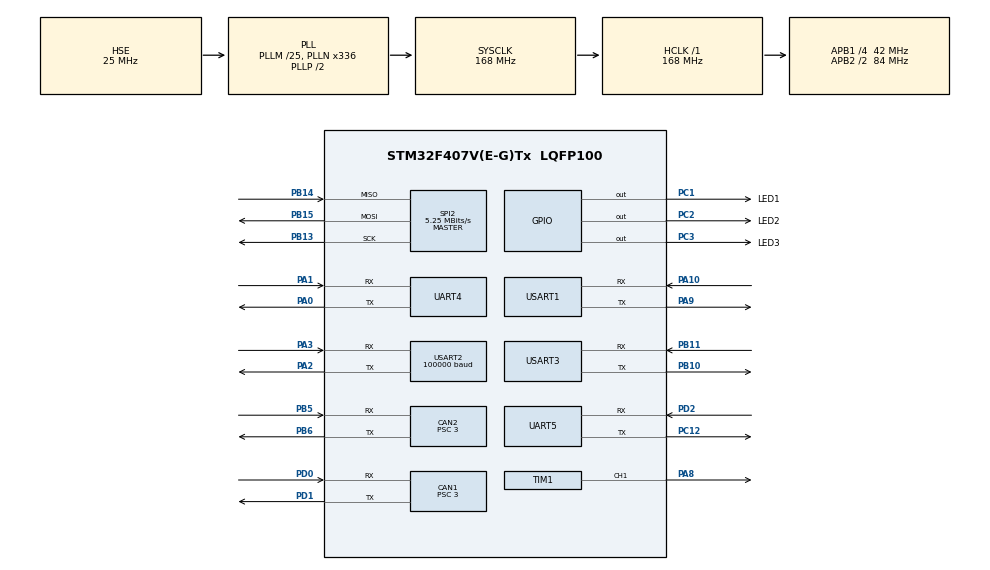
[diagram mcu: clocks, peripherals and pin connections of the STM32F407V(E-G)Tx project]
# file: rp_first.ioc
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CAN1.ABOM=ENABLE
CAN1.BS1=CAN_BS1_9TQ
CAN1.BS2=CAN_BS2_4TQ
CAN1.CalculateBaudRate=1000000
CAN1.CalculateTimeBit=1000
CAN1.CalculateTimeQuantum=71.42857142857143
CAN1.Prescaler=3
CAN2.ABOM=ENABLE
CAN2.BS1=CAN_BS1_9TQ
CAN2.BS2=CAN_BS2_4TQ
CAN2.CalculateBaudRate=1000000
CAN2.CalculateTimeBit=1000
CAN2.CalculateTimeQuantum=71.42857142857143
CAN2.Prescaler=3
Dma.Request0=UART4_RX
Dma.Request1=UART4_TX
Dma.Request2=USART1_RX
Dma.Request3=USART1_TX
Dma.Request4=UART5_RX
Dma.Request5=UART5_TX
Dma.Request6=USART2_RX
Dma.Request7=USART3_RX
Dma.Request8=USART3_TX
Dma.UART4_RX.0.Direction=DMA_PERIPH_TO_MEMORY
Dma.UART4_RX.0.FIFOMode=DMA_FIFOMODE_DISABLE
Dma.UART4_RX.0.Instance=DMA1_Stream2
Dma.UART4_RX.0.MemDataAlignment=DMA_MDATAALIGN_BYTE
Dma.UART4_RX.0.MemInc=DMA_MINC_ENABLE
Dma.UART4_RX.0.Mode=DMA_CIRCULAR
Dma.UART4_RX.0.PeriphDataAlignment=DMA_PDATAALIGN_BYTE
Dma.UART4_RX.0.PeriphInc=DMA_PINC_DISABLE
Dma.UART4_RX.0.Priority=DMA_PRIORITY_HIGH
Dma.UART4_TX.1.Direction=DMA_MEMORY_TO_PERIPH
Dma.UART4_TX.1.FIFOMode=DMA_FIFOMODE_DISABLE
Dma.UART4_TX.1.Instance=DMA1_Stream4
Dma.UART4_TX.1.MemDataAlignment=DMA_MDATAALIGN_BYTE
Dma.UART4_TX.1.MemInc=DMA_MINC_ENABLE
Dma.UART4_TX.1.Mode=DMA_NORMAL
Dma.UART4_TX.1.PeriphDataAlignment=DMA_PDATAALIGN_BYTE
Dma.UART4_TX.1.PeriphInc=DMA_PINC_DISABLE
Dma.UART4_TX.1.Priority=DMA_PRIORITY_HIGH
Dma.UART5_RX.4.Direction=DMA_PERIPH_TO_MEMORY
Dma.UART5_RX.4.FIFOMode=DMA_FIFOMODE_DISABLE
Dma.UART5_RX.4.Instance=DMA1_Stream0
Dma.UART5_RX.4.MemDataAlignment=DMA_MDATAALIGN_BYTE
Dma.UART5_RX.4.MemInc=DMA_MINC_ENABLE
Dma.UART5_RX.4.Mode=DMA_CIRCULAR
Dma.UART5_RX.4.PeriphDataAlignment=DMA_PDATAALIGN_BYTE
Dma.UART5_RX.4.PeriphInc=DMA_PINC_DISABLE
Dma.UART5_RX.4.Priority=DMA_PRIORITY_HIGH
Dma.UART5_TX.5.Direction=DMA_MEMORY_TO_PERIPH
Dma.UART5_TX.5.FIFOMode=DMA_FIFOMODE_DISABLE
Dma.UART5_TX.5.Instance=DMA1_Stream7
Dma.UART5_TX.5.MemDataAlignment=DMA_MDATAALIGN_BYTE
Dma.UART5_TX.5.MemInc=DMA_MINC_ENABLE
Dma.UART5_TX.5.Mode=DMA_NORMAL
Dma.UART5_TX.5.PeriphDataAlignment=DMA_PDATAALIGN_BYTE
Dma.UART5_TX.5.PeriphInc=DMA_PINC_DISABLE
Dma.UART5_TX.5.Priority=DMA_PRIORITY_HIGH
Dma.USART1_RX.2.Direction=DMA_PERIPH_TO_MEMORY
Dma.USART1_RX.2.FIFOMode=DMA_FIFOMODE_DISABLE
Dma.USART1_RX.2.Instance=DMA2_Stream2
Dma.USART1_RX.2.MemDataAlignment=DMA_MDATAALIGN_BYTE
Dma.USART1_RX.2.MemInc=DMA_MINC_ENABLE
Dma.USART1_RX.2.Mode=DMA_CIRCULAR
Dma.USART1_RX.2.PeriphDataAlignment=DMA_PDATAALIGN_BYTE
Dma.USART1_RX.2.PeriphInc=DMA_PINC_DISABLE
Dma.USART1_RX.2.Priority=DMA_PRIORITY_HIGH
Dma.USART1_TX.3.Direction=DMA_MEMORY_TO_PERIPH
Dma.USART1_TX.3.FIFOMode=DMA_FIFOMODE_DISABLE
Dma.USART1_TX.3.Instance=DMA2_Stream7
Dma.USART1_TX.3.MemDataAlignment=DMA_MDATAALIGN_BYTE
Dma.USART1_TX.3.MemInc=DMA_MINC_ENABLE
Dma.USART1_TX.3.Mode=DMA_NORMAL
Dma.USART1_TX.3.PeriphDataAlignment=DMA_PDATAALIGN_BYTE
Dma.USART1_TX.3.PeriphInc=DMA_PINC_DISABLE
Dma.USART1_TX.3.Priority=DMA_PRIORITY_HIGH
Dma.USART2_RX.6.Direction=DMA_PERIPH_TO_MEMORY
Dma.USART2_RX.6.FIFOMode=DMA_FIFOMODE_DISABLE
Dma.USART2_RX.6.Instance=DMA1_Stream5
Dma.USART2_RX.6.MemDataAlignment=DMA_MDATAALIGN_BYTE
Dma.USART2_RX.6.MemInc=DMA_MINC_ENABLE
Dma.USART2_RX.6.Mode=DMA_CIRCULAR
Dma.USART2_RX.6.PeriphDataAlignment=DMA_PDATAALIGN_BYTE
Dma.USART2_RX.6.PeriphInc=DMA_PINC_DISABLE
Dma.USART2_RX.6.Priority=DMA_PRIORITY_HIGH
Dma.USART3_RX.7.Direction=DMA_PERIPH_TO_MEMORY
Dma.USART3_RX.7.FIFOMode=DMA_FIFOMODE_DISABLE
Dma.USART3_RX.7.Instance=DMA1_Stream1
Dma.USART3_RX.7.MemDataAlignment=DMA_MDATAALIGN_BYTE
Dma.USART3_RX.7.MemInc=DMA_MINC_ENABLE
Dma.USART3_RX.7.Mode=DMA_CIRCULAR
Dma.USART3_RX.7.PeriphDataAlignment=DMA_PDATAALIGN_BYTE
Dma.USART3_RX.7.PeriphInc=DMA_PINC_DISABLE
Dma.USART3_RX.7.Priority=DMA_PRIORITY_LOW
Dma.USART3_TX.8.Direction=DMA_MEMORY_TO_PERIPH
Dma.USART3_TX.8.FIFOMode=DMA_FIFOMODE_DISABLE
Dma.USART3_TX.8.Instance=DMA1_Stream3
Dma.USART3_TX.8.MemDataAlignment=DMA_MDATAALIGN_BYTE
Dma.USART3_TX.8.MemInc=DMA_MINC_ENABLE
Dma.USART3_TX.8.Mode=DMA_NORMAL
Dma.USART3_TX.8.PeriphDataAlignment=DMA_PDATAALIGN_BYTE
Dma.USART3_TX.8.PeriphInc=DMA_PINC_DISABLE
Dma.USART3_TX.8.Priority=DMA_PRIORITY_LOW
FREERTOS.Tasks01=MonitorTask,3,256,StartMonitorTask,As weak,NULL,Dynamic,NULL,NULL;CommunityTask,2,512,StartCommunityTask,As weak,NULL,Dynamic,NULL,NULL;ControlTask,0,256,StartControlTask,As weak,NULL,Dynamic,NULL,NULL
FREERTOS.configENABLE_FPU=1
IWDG.Prescaler=IWDG_PRESCALER_8
Mcu.Family=STM32F4
Mcu.Name=STM32F407V(E-G)Tx
Mcu.Package=LQFP100
NVIC.CAN1_RX0_IRQn=true\:5\:0\:false\:false\:true\:true\:true\:true\:true
NVIC.CAN2_RX0_IRQn=true\:5\:0\:false\:false\:true\:true\:true\:true\:true
NVIC.DMA1_Stream0_IRQn=true\:5\:0\:false\:false\:true\:true\:false\:true\:true
NVIC.DMA1_Stream1_IRQn=true\:5\:0\:false\:false\:true\:true\:false\:true\:true
NVIC.DMA1_Stream2_IRQn=true\:5\:0\:false\:false\:true\:true\:false\:true\:true
NVIC.DMA1_Stream3_IRQn=true\:5\:0\:false\:false\:true\:true\:false\:true\:true
NVIC.DMA1_Stream4_IRQn=true\:5\:0\:false\:false\:true\:true\:false\:true\:true
NVIC.DMA1_Stream5_IRQn=true\:5\:0\:false\:false\:true\:true\:false\:true\:true
NVIC.DMA1_Stream7_IRQn=true\:5\:0\:false\:false\:true\:true\:false\:true\:true
NVIC.DMA2_Stream2_IRQn=true\:5\:0\:false\:false\:true\:true\:false\:true\:true
NVIC.DMA2_Stream7_IRQn=true\:5\:0\:false\:false\:true\:true\:false\:true\:true
NVIC.PriorityGroup=NVIC_PRIORITYGROUP_4
NVIC.TIM2_IRQn=true\:15\:0\:false\:false\:true\:false\:false\:true\:true
NVIC.TIM4_IRQn=true\:5\:0\:false\:false\:true\:true\:true\:true\:true
NVIC.TimeBase=TIM2_IRQn
NVIC.TimeBaseIP=TIM2
NVIC.UART4_IRQn=true\:5\:0\:false\:false\:true\:true\:true\:true\:true
NVIC.UART5_IRQn=true\:5\:0\:false\:false\:true\:true\:true\:true\:true
NVIC.USART1_IRQn=true\:5\:0\:false\:false\:true\:true\:true\:true\:true
NVIC.USART2_IRQn=true\:5\:0\:false\:false\:true\:true\:true\:true\:true
NVIC.USART3_IRQn=true\:5\:0\:false\:false\:true\:true\:true\:true\:true
PA0-WKUP.Mode=Asynchronous
PA0-WKUP.Signal=UART4_TX
PA1.Mode=Asynchronous
PA1.Signal=UART4_RX
PA10.Mode=Asynchronous
PA10.Signal=USART1_RX
PA13.Mode=Serial_Wire
PA13.Signal=SYS_JTMS-SWDIO
PA14.Mode=Serial_Wire
PA14.Signal=SYS_JTCK-SWCLK
PA2.Mode=Asynchronous
PA2.Signal=USART2_TX
PA3.Mode=Asynchronous
PA3.Signal=USART2_RX
PA8.Signal=S_TIM1_CH1
PA9.Mode=Asynchronous
PA9.Signal=USART1_TX
PB10.Mode=Asynchronous
PB10.Signal=USART3_TX
PB11.Mode=Asynchronous
PB11.Signal=USART3_RX
PB13.Mode=Full_Duplex_Master
PB13.Signal=SPI2_SCK
PB14.Mode=Full_Duplex_Master
PB14.Signal=SPI2_MISO
PB15.Mode=Full_Duplex_Master
PB15.Signal=SPI2_MOSI
PB5.Mode=CAN_Activate
PB5.Signal=CAN2_RX
PB6.Mode=CAN_Activate
PB6.Signal=CAN2_TX
PC1.GPIO_Label=LED1
PC1.GPIO_Speed=GPIO_SPEED_FREQ_LOW
PC1.PinState=GPIO_PIN_SET
PC1.Signal=GPIO_Output
PC12.Mode=Asynchronous
PC12.Signal=UART5_TX
PC2.GPIO_Label=LED2
PC2.PinState=GPIO_PIN_SET
PC2.Signal=GPIO_Output
PC3.GPIO_Label=LED3
PC3.PinState=GPIO_PIN_SET
PC3.Signal=GPIO_Output
PD0.Mode=CAN_Activate
PD0.Signal=CAN1_RX
PD1.Mode=CAN_Activate
PD1.Signal=CAN1_TX
PD2.Mode=Asynchronous
PD2.Signal=UART5_RX
PH0-OSC_IN.Mode=HSE-External-Oscillator
PH0-OSC_IN.Signal=RCC_OSC_IN
PH1-OSC_OUT.Mode=HSE-External-Oscillator
PH1-OSC_OUT.Signal=RCC_OSC_OUT
ProjectManager.HeapSize=0x200
ProjectManager.StackSize=0x400
ProjectManager.TargetToolchain=MDK-ARM V5.32
RCC.48MHZClocksFreq_Value=84000000
RCC.AHBFreq_Value=168000000
RCC.APB1CLKDivider=RCC_HCLK_DIV4
RCC.APB1Freq_Value=42000000
RCC.APB1TimFreq_Value=84000000
RCC.APB2CLKDivider=RCC_HCLK_DIV2
RCC.APB2Freq_Value=84000000
RCC.APB2TimFreq_Value=168000000
RCC.CortexFreq_Value=168000000
RCC.HCLKFreq_Value=168000000
RCC.HSE_VALUE=25000000
RCC.HSI_VALUE=16000000
RCC.LSE_VALUE=32768
RCC.PLLM=25
RCC.PLLN=336
RCC.PLLSourceVirtual=RCC_PLLSOURCE_HSE
RCC.SYSCLKFreq_VALUE=168000000
RCC.SYSCLKSource=RCC_SYSCLKSOURCE_PLLCLK
RCC.VCOOutputFreq_Value=336000000
SH.S_TIM1_CH1.0=TIM1_CH1,PWM Generation1 CH1
SPI2.BaudRatePrescaler=SPI_BAUDRATEPRESCALER_8
SPI2.CalculateBaudRate=5.25 MBits/s
SPI2.Direction=SPI_DIRECTION_2LINES
SPI2.Mode=SPI_MODE_MASTER
SPI2.VirtualType=VM_MASTER
TIM1.Channel-PWM\ Generation1\ CH1=TIM_CHANNEL_1
TIM1.Period=1000-1
TIM1.Prescaler=1680-1
TIM4.Period=6000-1
TIM4.Prescaler=8400-1
UART4.VirtualMode=Asynchronous
UART5.VirtualMode=Asynchronous
USART1.VirtualMode=VM_ASYNC
USART2.BaudRate=100000
USART2.Mode=MODE_RX
USART2.Parity=PARITY_EVEN
USART2.VirtualMode=VM_ASYNC
USART3.VirtualMode=VM_ASYNC
VP_FREERTOS_VS_CMSIS_V1.Mode=CMSIS_V1
VP_IWDG_VS_IWDG.Mode=IWDG_Activate
VP_SYS_VS_tim2.Mode=TIM2
VP_TIM1_VS_ClockSourceINT.Mode=Internal
VP_TIM4_VS_ClockSourceINT.Mode=Internal
board=custom

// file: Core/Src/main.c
/* USER CODE BEGIN Header */
/**
  ******************************************************************************
  * @file           : main.c
  * @brief          : Main program body
  ******************************************************************************
  * @attention
  *
  * Copyright (c) 2023 STMicroelectronics.
  * All rights reserved.
  *
  * This software is licensed under terms that can be found in the LICENSE file
  * in the root directory of this software component.
  * If no LICENSE file comes with this software, it is provided AS-IS.
  *
  ******************************************************************************
  */
/* USER CODE END Header */
#include "main.h"
#include "cmsis_os.h"
#include "can.h"
#include "dma.h"
#include "iwdg.h"
#include "spi.h"
#include "tim.h"
#include "usart.h"
#include "gpio.h"

/* USER CODE BEGIN Includes */
#include "RP_INIT.h"
/* USER CODE END Includes */

void SystemClock_Config(void);
void MX_FREERTOS_Init(void);

int main(void)
{

  /* MCU Configuration--------------------------------------------------------*/

  /* Reset of all peripherals, Initializes the Flash interface and the Systick. */
  HAL_Init();

  /* Configure the system clock */
  SystemClock_Config();

  /* Initialize all configured peripherals */
  MX_GPIO_Init();
  MX_DMA_Init();
  MX_TIM1_Init();
  MX_TIM4_Init();
  MX_CAN1_Init();
  MX_CAN2_Init();
  MX_UART4_Init();
  MX_UART5_Init();
  MX_USART1_UART_Init();
  MX_USART2_UART_Init();
  MX_USART3_UART_Init();
  MX_IWDG_Init();
  MX_SPI2_Init();
  /* USER CODE BEGIN 2 */

	HAL_IWDG_Refresh(&hiwdg);

	RP_INIT();

	HAL_IWDG_Refresh(&hiwdg);

  /* USER CODE END 2 */

  /* Call init function for freertos objects (in freertos.c) */
  MX_FREERTOS_Init();

  /* Start scheduler */
  osKernelStart();
  /* We should never get here as control is now taken by the scheduler */
  /* Infinite loop */
  while (1)
  {

  }
}

void SystemClock_Config(void)
{
  RCC_OscInitTypeDef RCC_OscInitStruct = {0};
  RCC_ClkInitTypeDef RCC_ClkInitStruct = {0};

  /** Configure the main internal regulator output voltage
  */
  __HAL_RCC_PWR_CLK_ENABLE();
  __HAL_PWR_VOLTAGESCALING_CONFIG(PWR_REGULATOR_VOLTAGE_SCALE1);

  /** Initializes the RCC Oscillators according to the specified parameters
  * in the RCC_OscInitTypeDef structure.
  */
  RCC_OscInitStruct.OscillatorType = RCC_OSCILLATORTYPE_LSI|RCC_OSCILLATORTYPE_HSE;
  RCC_OscInitStruct.HSEState = RCC_HSE_ON;
  RCC_OscInitStruct.LSIState = RCC_LSI_ON;
  RCC_OscInitStruct.PLL.PLLState = RCC_PLL_ON;
  RCC_OscInitStruct.PLL.PLLSource = RCC_PLLSOURCE_HSE;
  RCC_OscInitStruct.PLL.PLLM = 25;
  RCC_OscInitStruct.PLL.PLLN = 336;
  RCC_OscInitStruct.PLL.PLLP = RCC_PLLP_DIV2;
  RCC_OscInitStruct.PLL.PLLQ = 4;
  if (HAL_RCC_OscConfig(&RCC_OscInitStruct) != HAL_OK)
  {
    Error_Handler();
  }

  /** Initializes the CPU, AHB and APB buses clocks
  */
  RCC_ClkInitStruct.ClockType = RCC_CLOCKTYPE_HCLK|RCC_CLOCKTYPE_SYSCLK
                              |RCC_CLOCKTYPE_PCLK1|RCC_CLOCKTYPE_PCLK2;
  RCC_ClkInitStruct.SYSCLKSource = RCC_SYSCLKSOURCE_PLLCLK;
  RCC_ClkInitStruct.AHBCLKDivider = RCC_SYSCLK_DIV1;
  RCC_ClkInitStruct.APB1CLKDivider = RCC_HCLK_DIV4;
  RCC_ClkInitStruct.APB2CLKDivider = RCC_HCLK_DIV2;

  if (HAL_RCC_ClockConfig(&RCC_ClkInitStruct, FLASH_LATENCY_5) != HAL_OK)
  {
    Error_Handler();
  }
}

void HAL_TIM_PeriodElapsedCallback(TIM_HandleTypeDef *htim)
{
  if (htim->Instance == TIM2) {
    HAL_IncTick();
  }
}

void Error_Handler(void)
{
  __disable_irq();
  while (1)
  {
  }
}
